# ESP32S31_RADIO register map
Vendor: Espressif; Series: ESP32-S31; File version: 3.52
Registers are 32-bit, read-write, no defined reset value unless marked. A register's access mark holds for its fields unless they carry their own. Offsets are from the block's base; [hi:lo] are bit positions; {n}, {i} and the like mark numbered series; 'fields as' and 'values as' point back to an identical list.

## IEEE802154_MAC — Dedicated ESP32-S31 IEEE 802.15.4 MAC aperture at 0x20103000. This selective foundation publishes only register geometry exercised by the pinned public common/chip LL accessors. The public struct and register headers still carry TODO ZB-93 pending an authoritative regdesc CSV, so untouched DTM, timing, debug-selector and modem-sleep words remain deliberately absent and no reset values are claimed.
Base 0x20103000
0x00 COMMAND wo — Write-only IEEE 802.15.4 MAC command opcode. The public common LL constrains commands to the listed values.
  [7:0] OPCODE
    on write: 65=TX_START; 66=RX_START; 67=CCA_TX_START; 68=ED_START; 69=STOP; 70=TEST_TX_START; 71=TEST_RX_START; 72=TEST_STOP; 76=TIMER0_START; 77=TIMER0_STOP; 78=TIMER1_START; 79=TIMER1_STOP
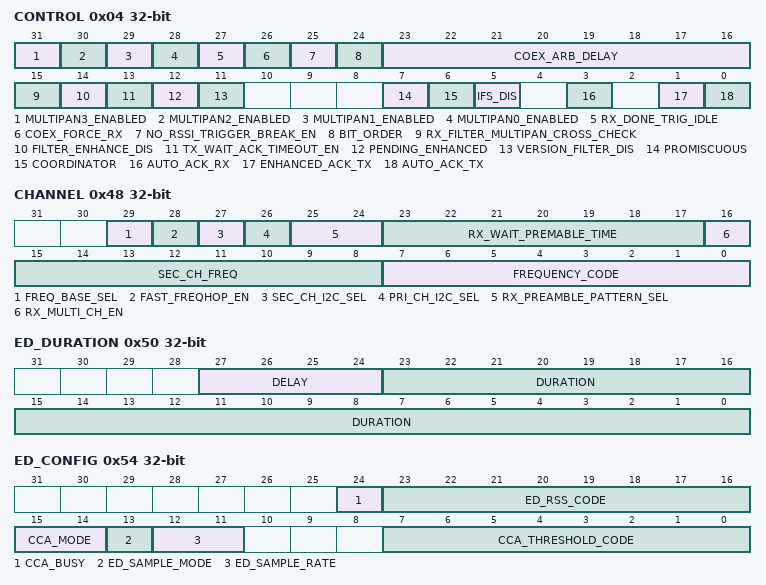
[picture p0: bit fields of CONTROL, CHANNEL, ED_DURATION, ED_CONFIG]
0x04 CONTROL — Project-assigned name. Selected MAC policy bits mutated by public common LL accessors. Unused control bits remain absent.
  [31] MULTIPAN3_ENABLED — Project-assigned name. Enable public multipan context three.
  [30] MULTIPAN2_ENABLED — Project-assigned name. Enable public multipan context two.
  [29] MULTIPAN1_ENABLED — Project-assigned name. Enable public multipan context one.
  [28] MULTIPAN0_ENABLED — Project-assigned name. Enable public multipan context zero.
  [27] RX_DONE_TRIG_IDLE — Project-assigned name. Open vendor conf.rx_done_trig_idle field. SOURCE: ESP_IDF_7B9CC1AC_S31_IEEE802154_STRUCT. No reset or additional access semantics are inferred.
  [26] COEX_FORCE_RX — Project-assigned name. Open vendor conf.coex_force_rx field. SOURCE: ESP_IDF_7B9CC1AC_S31_IEEE802154_STRUCT. No reset or additional access semantics are inferred.
  [25] NO_RSSI_TRIGGER_BREAK_EN — Project-assigned name. Open vendor conf.no_rssi_trigger_break_en field. SOURCE: ESP_IDF_7B9CC1AC_S31_IEEE802154_STRUCT. No reset or additional access semantics are inferred.
  [24] BIT_ORDER — Project-assigned name. Open vendor conf.bit_order field. SOURCE: ESP_IDF_7B9CC1AC_S31_IEEE802154_STRUCT. No reset or additional access semantics are inferred.
  [23:16] COEX_ARB_DELAY — Project-assigned name. Open vendor conf.coex_arb_delay field. SOURCE: ESP_IDF_7B9CC1AC_S31_IEEE802154_STRUCT. No reset or additional access semantics are inferred.
  [15] RX_FILTER_MULTIPAN_CROSS_CHECK — Project-assigned name. Open vendor conf.rx_filter_multipan_cross_check field. SOURCE: ESP_IDF_7B9CC1AC_S31_IEEE802154_STRUCT. No reset or additional access semantics are inferred.
  [14] FILTER_ENHANCE_DIS — Project-assigned name. Open vendor conf.filter_enhance_dis field. SOURCE: ESP_IDF_7B9CC1AC_S31_IEEE802154_STRUCT. No reset or additional access semantics are inferred.
  [13] TX_WAIT_ACK_TIMEOUT_EN — Project-assigned name. Open vendor conf.tx_wait_ack_timeout_en field. SOURCE: ESP_IDF_7B9CC1AC_S31_IEEE802154_STRUCT. No reset or additional access semantics are inferred.
  [12] PENDING_ENHANCED — Project-assigned name. Boolean pending-mode selector used by the current public LL. The wider public pending-mode enum is not encoded in this one-bit field.
  [11] VERSION_FILTER_DIS — Project-assigned name. Open vendor conf.version_filter_dis field. SOURCE: ESP_IDF_7B9CC1AC_S31_IEEE802154_STRUCT. No reset or additional access semantics are inferred.
  [7] PROMISCUOUS — Project-assigned name.
  [6] COORDINATOR — Project-assigned name.
  [5] IFS_DIS — Project-assigned name. Open vendor conf.ifs_dis field. SOURCE: ESP_IDF_7B9CC1AC_S31_IEEE802154_STRUCT. No reset or additional access semantics are inferred.
  [3] AUTO_ACK_RX — Project-assigned name.
  [1] ENHANCED_ACK_TX — Project-assigned name.
  [0] AUTO_ACK_TX — Project-assigned name.
{0x8+0x10*i} MULTIPAN{i}_SHORT_ADDRESS (i=0..3) — Project-assigned name. Sixteen-bit short address for one public multipan context.
  [15:0] ADDRESS — Project-assigned name.
{0xC+0x10*i} MULTIPAN{i}_PAN_ID (i=0..3) — Project-assigned name. Sixteen-bit PAN identifier for one public multipan context.
  [15:0] PAN_ID — Project-assigned name.
{0x10+0x10*i} MULTIPAN{i}_EXTENDED_ADDRESS_LOW (i=0..3) — Project-assigned name. Extended-address bytes zero through three packed little-endian by the public common LL.
  [31:0] ADDRESS_WORD — Project-assigned name.
{0x14+0x10*i} MULTIPAN{i}_EXTENDED_ADDRESS_HIGH (i=0..3) — Project-assigned name. Extended-address bytes four through seven packed little-endian by the public common LL.
  [31:0] ADDRESS_WORD — Project-assigned name.
0x48 CHANNEL — Selected primary frequency code. Other multi-channel and frequency-hop controls declared by the struct are not used by the public common LL and remain absent.
  [29] FREQ_BASE_SEL — Project-assigned name. Open vendor channel.freq_base_sel field. SOURCE: ESP_IDF_7B9CC1AC_S31_IEEE802154_STRUCT. No reset or additional access semantics are inferred.
  [28] FAST_FREQHOP_EN — Project-assigned name. Open vendor channel.fast_freqhop_en field. SOURCE: ESP_IDF_7B9CC1AC_S31_IEEE802154_STRUCT. No reset or additional access semantics are inferred.
  [27] SEC_CH_I2C_SEL — Project-assigned name. Open vendor channel.sec_ch_i2c_sel field. SOURCE: ESP_IDF_7B9CC1AC_S31_IEEE802154_STRUCT. No reset or additional access semantics are inferred.
  [26] PRI_CH_I2C_SEL — Project-assigned name. Open vendor channel.pri_ch_i2c_sel field. SOURCE: ESP_IDF_7B9CC1AC_S31_IEEE802154_STRUCT. No reset or additional access semantics are inferred.
  [25:24] RX_PREAMBLE_PATTERN_SEL — Project-assigned name. Open vendor channel.rx_preamble_pattern_sel field. SOURCE: ESP_IDF_7B9CC1AC_S31_IEEE802154_STRUCT. No reset or additional access semantics are inferred.
  [23:17] RX_WAIT_PREMABLE_TIME — Project-assigned name. Open vendor channel.rx_wait_premable_time field. SOURCE: ESP_IDF_7B9CC1AC_S31_IEEE802154_STRUCT. No reset or additional access semantics are inferred.
  [16] RX_MULTI_CH_EN — Project-assigned name. Open vendor channel.rx_multi_ch_en field. SOURCE: ESP_IDF_7B9CC1AC_S31_IEEE802154_STRUCT. No reset or additional access semantics are inferred.
  [15:8] SEC_CH_FREQ — Project-assigned name. Open vendor channel.sec_ch_freq field. SOURCE: ESP_IDF_7B9CC1AC_S31_IEEE802154_STRUCT. No reset or additional access semantics are inferred.
  [7:0] FREQUENCY_CODE — Project-assigned name. Eight-bit code read and written by ieee802154_ll_get_freq/set_freq; this register model does not equate it to an IEEE channel number.
0x4C TX_POWER — Eight-bit transmit-power code written through a preserving bitfield update by the public common LL.
  [7:0] POWER_CODE — Project-assigned name. Raw eight-bit hardware code; no dBm conversion is claimed at the register boundary.
0x50 ED_DURATION — Project-assigned name. Energy-detection duration field written by the public common LL. The adjacent delay field is not used there and remains absent.
  [27:24] DELAY — Project-assigned name. Open vendor ed_duration.delay field. SOURCE: ESP_IDF_7B9CC1AC_S31_IEEE802154_STRUCT. No reset or additional access semantics are inferred.
  [23:0] DURATION — Project-assigned name. Twenty-four-bit physical field. The current public setter accepts only a uint16_t and therefore exercises a strict subset of its declared range.
0x54 ED_CONFIG — Project-assigned name. Energy-detection and clear-channel-assessment configuration plus read-only result fields used by the public common LL. The pinned reg macros call bits 12:11 ED_SAMPLE_MODE and bit 13 DIS_ED_POWER_SEL, while the pinned struct/common LL operate them as ED_SAMPLE_RATE and ED_SAMPLE_MODE respectively; this model follows the operational struct/common-LL pair and leaves the naming conflict explicit.
  [24] CCA_BUSY ro
  [23:16] ED_RSS_CODE ro — Project-assigned name. Eight-bit result returned as int8_t by the public common LL.
  [15:14] CCA_MODE
    on write: 0=CARRIER; 1=ENERGY_DETECTION; 2=CARRIER_OR_ENERGY_DETECTION; 3=CARRIER_AND_ENERGY_DETECTION
  [13] ED_SAMPLE_MODE
    on write: 0=MAXIMUM; 1=AVERAGE
  [12:11] ED_SAMPLE_RATE — Project-assigned name.
    on write: 0=ONE_PER_US; 1=TWO_PER_US; 2=FOUR_PER_US; 3=EIGHT_PER_US
  [7:0] CCA_THRESHOLD_CODE — Project-assigned name. Eight-bit code written from an int8_t; signed physical units are intentionally left to the HAL.
0x5C ACK_TIMEOUT — Sixteen-bit acknowledgment timeout read and written by the public common LL. Units are not assigned by this register model.
  [15:0] TIMEOUT — Project-assigned name.
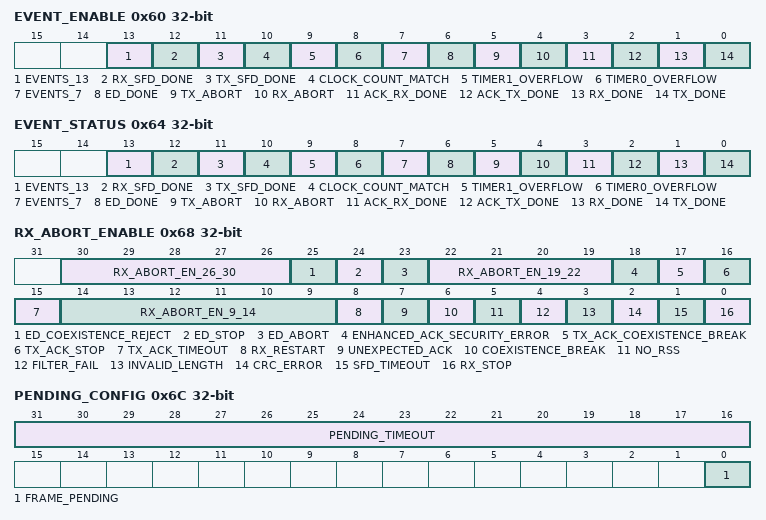
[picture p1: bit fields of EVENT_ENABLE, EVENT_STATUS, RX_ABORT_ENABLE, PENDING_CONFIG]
0x60 EVENT_ENABLE — Project-assigned name. Individual event enables mutated by the public common LL. All fourteen lanes belong to the open vendor events field; individual unnamed events remain descriptive partitions.
  [13] EVENTS_13 — Project-assigned name. Partition of the open vendor events field, bits 13:13; no individual event/reason meaning is assigned. SOURCE: ESP_IDF_7B9CC1AC_S31_IEEE802154_STRUCT.
  [12] RX_SFD_DONE — Project-assigned name.
  [11] TX_SFD_DONE — Project-assigned name.
  [10] CLOCK_COUNT_MATCH — Project-assigned name.
  [9] TIMER1_OVERFLOW — Project-assigned name.
  [8] TIMER0_OVERFLOW — Project-assigned name.
  [7] EVENTS_7 — Project-assigned name. Partition of the open vendor events field, bits 7:7; no individual event/reason meaning is assigned. SOURCE: ESP_IDF_7B9CC1AC_S31_IEEE802154_STRUCT.
  [6] ED_DONE — Project-assigned name.
  [5] TX_ABORT — Project-assigned name.
  [4] RX_ABORT — Project-assigned name.
  [3] ACK_RX_DONE — Project-assigned name.
  [2] ACK_TX_DONE — Project-assigned name.
  [1] RX_DONE — Project-assigned name.
  [0] TX_DONE — Project-assigned name.
0x64 EVENT_STATUS write-1-clears — Project-assigned name. Individual event status bits read by the public LL. The target-reviewed overlay assigns the read-write W1C contract for the applicable ESP32-S31 revision; unnamed event lanes remain partitions of the open vendor events field.
  fields as EVENT_ENABLE
0x68 RX_ABORT_ENABLE — Project-assigned name. Low thirty-one receive-abort enable bits mutated by public LL accessors. Only the finite abort-reason values named by the LL are semantically classified.
  [30:26] RX_ABORT_EN_26_30 — Project-assigned name. Partition of the open vendor rx_abort_en field, bits 30:26; no individual event/reason meaning is assigned. SOURCE: ESP_IDF_7B9CC1AC_S31_IEEE802154_STRUCT.
  [25] ED_COEXISTENCE_REJECT — Project-assigned name. Enable bit of abort reason 26 (ed coexistence reject).
  [24] ED_STOP — Project-assigned name. Enable bit of abort reason 25 (ed stop).
  [23] ED_ABORT — Project-assigned name. Enable bit of abort reason 24 (ed abort).
  [22:19] RX_ABORT_EN_19_22 — Project-assigned name. Partition of the open vendor rx_abort_en field, bits 22:19; no individual event/reason meaning is assigned. SOURCE: ESP_IDF_7B9CC1AC_S31_IEEE802154_STRUCT.
  [18] ENHANCED_ACK_SECURITY_ERROR — Project-assigned name. Enable bit of abort reason 19 (enhanced ack security error).
  [17] TX_ACK_COEXISTENCE_BREAK — Project-assigned name. Enable bit of abort reason 18 (tx ack coexistence break).
  [16] TX_ACK_STOP — Project-assigned name. Enable bit of abort reason 17 (tx ack stop).
  [15] TX_ACK_TIMEOUT — Project-assigned name. Enable bit of abort reason 16 (tx ack timeout).
  [14:9] RX_ABORT_EN_9_14 — Project-assigned name. Partition of the open vendor rx_abort_en field, bits 14:9; no individual event/reason meaning is assigned. SOURCE: ESP_IDF_7B9CC1AC_S31_IEEE802154_STRUCT.
  [8] RX_RESTART — Project-assigned name. Enable bit of abort reason 9 (rx restart).
  [7] UNEXPECTED_ACK — Project-assigned name. Enable bit of abort reason 8 (unexpected ack).
  [6] COEXISTENCE_BREAK — Project-assigned name. Enable bit of abort reason 7 (coexistence break).
  [5] NO_RSS — Project-assigned name. Enable bit of abort reason 6 (no rss).
  [4] FILTER_FAIL — Project-assigned name. Enable bit of abort reason 5 (filter fail).
  [3] INVALID_LENGTH — Project-assigned name. Enable bit of abort reason 4 (invalid length).
  [2] CRC_ERROR — Project-assigned name. Enable bit of abort reason 3 (crc error).
  [1] SFD_TIMEOUT — Project-assigned name. Enable bit of abort reason 2 (sfd timeout).
  [0] RX_STOP — Project-assigned name. Enable bit of abort reason 1 (rx stop).
0x6C PENDING_CONFIG — Project-assigned name. Selected outgoing acknowledgment frame-pending bit. The untouched timeout field remains absent.
  [31:16] PENDING_TIMEOUT — Project-assigned name. Open vendor pending_cfg.pending_timeout field. SOURCE: ESP_IDF_7B9CC1AC_S31_IEEE802154_STRUCT. No reset or additional access semantics are inferred.
  [0] FRAME_PENDING — Project-assigned name.
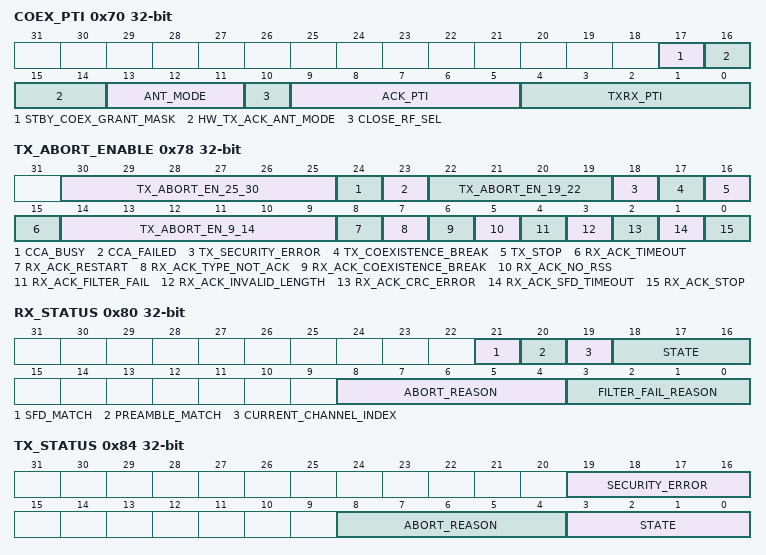
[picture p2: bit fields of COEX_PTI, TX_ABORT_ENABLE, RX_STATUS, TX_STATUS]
0x70 COEX_PTI — Selected coexistence priority fields. The public disable-coexistence helper writes value three to each through two preserving field updates. Other antenna and RF controls remain absent.
  [17] STBY_COEX_GRANT_MASK — Project-assigned name. Open vendor pti.stby_coex_grant_mask field. SOURCE: ESP_IDF_7B9CC1AC_S31_IEEE802154_STRUCT. No reset or additional access semantics are inferred.
  [16:14] HW_TX_ACK_ANT_MODE — Project-assigned name. Open vendor pti.hw_tx_ack_ant_mode field. SOURCE: ESP_IDF_7B9CC1AC_S31_IEEE802154_STRUCT. No reset or additional access semantics are inferred.
  [13:11] ANT_MODE — Project-assigned name. Open vendor pti.ant_mode field. SOURCE: ESP_IDF_7B9CC1AC_S31_IEEE802154_STRUCT. No reset or additional access semantics are inferred.
  [10] CLOSE_RF_SEL — Project-assigned name. Open vendor pti.close_rf_sel field. SOURCE: ESP_IDF_7B9CC1AC_S31_IEEE802154_STRUCT. No reset or additional access semantics are inferred.
  [9:5] ACK_PTI — Project-assigned name.
  [4:0] TXRX_PTI — Project-assigned name.
0x78 TX_ABORT_ENABLE — Project-assigned name. Low thirty-one transmit-abort enable bits mutated by public LL accessors. Only the finite abort-reason values named by the LL are semantically classified.
  [30:25] TX_ABORT_EN_25_30 — Project-assigned name. Partition of the open vendor tx_abort_en field, bits 30:25; no individual event/reason meaning is assigned. SOURCE: ESP_IDF_7B9CC1AC_S31_IEEE802154_STRUCT.
  [24] CCA_BUSY — Project-assigned name. Enable bit of abort reason 25 (cca busy).
  [23] CCA_FAILED — Project-assigned name. Enable bit of abort reason 24 (cca failed).
  [22:19] TX_ABORT_EN_19_22 — Project-assigned name. Partition of the open vendor tx_abort_en field, bits 22:19; no individual event/reason meaning is assigned. SOURCE: ESP_IDF_7B9CC1AC_S31_IEEE802154_STRUCT.
  [18] TX_SECURITY_ERROR — Project-assigned name. Enable bit of abort reason 19 (tx security error).
  [17] TX_COEXISTENCE_BREAK — Project-assigned name. Enable bit of abort reason 18 (tx coexistence break).
  [16] TX_STOP — Project-assigned name. Enable bit of abort reason 17 (tx stop).
  [15] RX_ACK_TIMEOUT — Project-assigned name. Enable bit of abort reason 16 (rx ack timeout).
  [14:9] TX_ABORT_EN_9_14 — Project-assigned name. Partition of the open vendor tx_abort_en field, bits 14:9; no individual event/reason meaning is assigned. SOURCE: ESP_IDF_7B9CC1AC_S31_IEEE802154_STRUCT.
  [8] RX_ACK_RESTART — Project-assigned name. Enable bit of abort reason 9 (rx ack restart).
  [7] RX_ACK_TYPE_NOT_ACK — Project-assigned name. Enable bit of abort reason 8 (rx ack type not ack).
  [6] RX_ACK_COEXISTENCE_BREAK — Project-assigned name. Enable bit of abort reason 7 (rx ack coexistence break).
  [5] RX_ACK_NO_RSS — Project-assigned name. Enable bit of abort reason 6 (rx ack no rss).
  [4] RX_ACK_FILTER_FAIL — Project-assigned name. Enable bit of abort reason 5 (rx ack filter fail).
  [3] RX_ACK_INVALID_LENGTH — Project-assigned name. Enable bit of abort reason 4 (rx ack invalid length).
  [2] RX_ACK_CRC_ERROR — Project-assigned name. Enable bit of abort reason 3 (rx ack crc error).
  [1] RX_ACK_SFD_TIMEOUT — Project-assigned name. Enable bit of abort reason 2 (rx ack sfd timeout).
  [0] RX_ACK_STOP — Project-assigned name. Enable bit of abort reason 1 (rx ack stop).
0x7C ENHANCED_ACK_NOTIFY wo — Project-assigned name. Write-only enhanced-ack generation-done notification word. The public common LL writes the complete value one; trigger/clear behavior is not inferred.
  [31:0] NOTIFY_IMAGE — Project-assigned name.
0x80 RX_STATUS ro — Receive status snapshot returned whole by the public common LL; selected subfields are independently named by the struct and accessor set.
  [21] SFD_MATCH
  [20] PREAMBLE_MATCH
  [19] CURRENT_CHANNEL_INDEX — Project-assigned name.
  [18:16] STATE — Project-assigned name. Three-bit receive state. The public LL only establishes that value one is RECEIVE_SFD and tests for later states with a greater-than comparison.
  [8:4] ABORT_REASON — Project-assigned name.
    on read: 1=RX_STOP; 2=SFD_TIMEOUT; 3=CRC_ERROR; 4=INVALID_LENGTH; 5=FILTER_FAIL; 6=NO_RSS; 7=COEX_BREAK; 8=UNEXPECTED_ACK; 9=RX_RESTART; 16=TX_ACK_TIMEOUT; 17=TX_ACK_STOP; 18=TX_ACK_COEX_BREAK; 19=ENHANCED_ACK_SECURITY_ERROR; 24=ED_ABORT; 25=ED_STOP; 26=ED_COEX_REJECT
  [3:0] FILTER_FAIL_REASON — Project-assigned name.
0x84 TX_STATUS ro — Transmit status snapshot returned whole by the public common LL; abort and security-error subfields have public finite reason enums.
  [19:16] SECURITY_ERROR — Project-assigned name.
    on read: 1=FRAME_CONTROL_NOT_SET; 2=RESERVED_SECURITY_LEVEL; 3=HEADER_PARSE; 4=PAYLOAD_ERROR; 5=FRAME_COUNTER_SUPPRESSION
  [8:4] ABORT_REASON — Project-assigned name.
    on read: 1=RX_ACK_STOP; 2=RX_ACK_SFD_TIMEOUT; 3=RX_ACK_CRC_ERROR; 4=RX_ACK_INVALID_LENGTH; 5=RX_ACK_FILTER_FAIL; 6=RX_ACK_NO_RSS; 7=RX_ACK_COEX_BREAK; 8=RX_ACK_TYPE_NOT_ACK; 9=RX_ACK_RESTART; 16=RX_ACK_TIMEOUT; 17=TX_STOP; 18=TX_COEX_BREAK; 19=TX_SECURITY_ERROR; 24=CCA_FAILED; 25=CCA_BUSY
  [3:0] STATE — Project-assigned name.
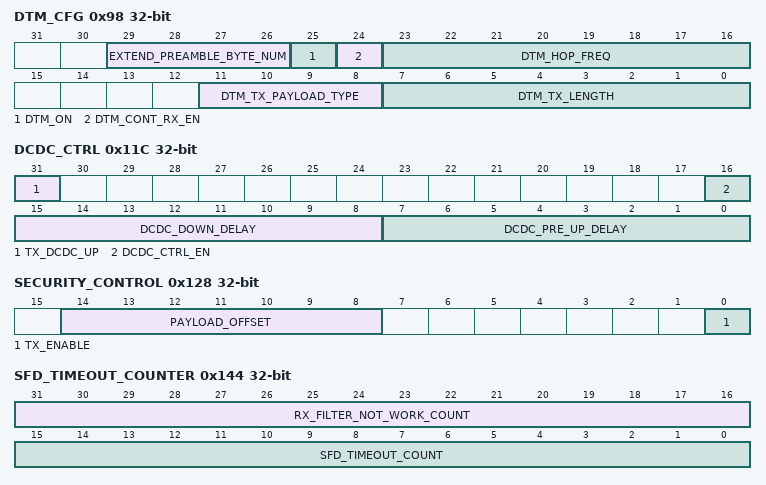
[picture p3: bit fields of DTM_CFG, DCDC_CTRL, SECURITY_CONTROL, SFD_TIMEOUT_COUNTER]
0x98 DTM_CFG access not given — Project-assigned name. Open vendor dtm_cfg word. SOURCE: ESP_IDF_7B9CC1AC_S31_IEEE802154_STRUCT. No reset value is claimed.
  [29:26] EXTEND_PREAMBLE_BYTE_NUM — Project-assigned name.
  [25] DTM_ON — Project-assigned name.
  [24] DTM_CONT_RX_EN — Project-assigned name.
  [23:16] DTM_HOP_FREQ — Project-assigned name.
  [11:8] DTM_TX_PAYLOAD_TYPE — Project-assigned name.
  [7:0] DTM_TX_LENGTH — Project-assigned name.
0xA8 TIMER0_THRESHOLD wo — Project-assigned name. Complete timer-zero threshold word written by the public common LL.
  [31:0] THRESHOLD — Project-assigned name.
0xAC TIMER0_VALUE ro — Project-assigned name. Complete timer-zero value word read by the public common LL.
  [31:0] VALUE — Project-assigned name.
0xB0 TIMER1_THRESHOLD wo — Project-assigned name. Complete timer-one threshold word written by the public common LL.
  [31:0] THRESHOLD — Project-assigned name.
0xB4 TIMER1_VALUE ro — Project-assigned name. Complete timer-one value word read by the public common LL.
  [31:0] VALUE — Project-assigned name.
0xC4 SFD_WAIT access not given — Project-assigned name. Open vendor sfd_wait word. SOURCE: ESP_IDF_7B9CC1AC_S31_IEEE802154_STRUCT. No reset value is claimed.
  [3:0] SFD_WAIT_SYMBOL_NUM — Project-assigned name.
0xD0 TX_DMA_ADDRESS wo — Project-assigned name. Complete transmit frame-buffer address written by the public common LL. Address validity and buffer lifetime remain HAL responsibilities.
  [31:0] ADDRESS — Project-assigned name.
0xD8 TXDMA_ERR ro — Transmit DMA error code, named by the public register header; no public LL accessor reads it.
  [3:0] TXDMA_ERR — Transmit DMA error code; no value is assigned a meaning.
0xE0 RX_DMA_ADDRESS wo — Project-assigned name. Complete receive frame-buffer address written by the public common LL. Address validity and buffer lifetime remain HAL responsibilities.
  [31:0] ADDRESS — Project-assigned name.
0xE8 RXDMA_ERR ro — Receive DMA error code, named by the public register header; no public LL accessor reads it.
  [3:0] RXDMA_ERR — Receive DMA error code; no value is assigned a meaning.
0x100 PAON_DELAY — Power-amplifier-on delay. The pinned public driver and LL never write it; the reset value applies unless another owner does. Physical units remain outside the PAC.
  [9:0] PAON_DELAY — Ten-bit power-amplifier-on delay.
0x104 TXON_DELAY — Transmit-on delay written by the pinned ESP32-S31 IEEE 802.15.4 MAC initializer. The literal value 45 is reviewed; Physical units remain outside the PAC.
  [9:0] TXON_DELAY — Ten-bit preserving field written with literal 45 by ieee802154_txon_delay_set.
0x108 TXEN_STOP_DELAY — Transmit-enable stop delay. The pinned public driver and LL never write it; physical units remain outside the PAC.
  [5:0] TXEN_STOP_DLY — Six-bit transmit-enable stop delay.
0x10C TXOFF_DELAY — Transmit-off delay written by the pinned ESP32-S31 IEEE 802.15.4 MAC initializer. The literal value 5 is reviewed; Physical units remain outside the PAC.
  [5:0] TXOFF_DELAY — Six-bit preserving field written with literal 5 by ieee802154_txon_delay_set.
0x110 RXON_DELAY — Receive-on delay written by the pinned ESP32-S31 IEEE 802.15.4 MAC initializer. The literal value 50 is reviewed; Physical units remain outside the PAC.
  [10:0] RXON_DELAY — Eleven-bit preserving field written with literal 50 by ieee802154_txon_delay_set.
0x114 TXRX_SWITCH_DELAY — Transmit/receive turnaround delay written by the pinned ESP32-S31 IEEE 802.15.4 MAC initializer. The literal value 117 is reviewed; Physical units remain outside the PAC.
  [9:0] TXRX_SWITCH_DELAY — Ten-bit preserving field written with literal 117 by ieee802154_txon_delay_set.
0x118 CONT_RX_DELAY — Continuous-receive delay. The pinned public driver and LL never write it; physical units remain outside the PAC.
  [5:0] CONT_RX_DELAY — Six-bit continuous-receive delay.
0x11C DCDC_CTRL — MAC control of the DC-DC converter around transmission. The pinned public driver and LL never write it; physical units of the delays remain outside the PAC.
  [31] TX_DCDC_UP — Raise the DC-DC converter for transmission.
  [16] DCDC_CTRL_EN — The MAC controls the DC-DC converter.
  [15:8] DCDC_DOWN_DELAY — Delay before the DC-DC drop.
  [7:0] DCDC_PRE_UP_DELAY — Delay before the DC-DC raise.
0x128 SECURITY_CONTROL — Project-assigned name. Transmit-security enable and payload-offset fields used by the public common LL.
  [14:8] PAYLOAD_OFFSET — Project-assigned name.
  [0] TX_ENABLE — Project-assigned name.
0x12C SECURITY_ADDRESS_LOW wo — Project-assigned name. Security extended-address bytes zero through three packed little-endian by the public common LL.
  [31:0] ADDRESS_WORD — Project-assigned name.
0x130 SECURITY_ADDRESS_HIGH wo — Project-assigned name. Security extended-address bytes four through seven packed little-endian by the public common LL.
  [31:0] ADDRESS_WORD — Project-assigned name.
{0x134+4i} SECURITY_KEY{i} (i=0..3) wo — Project-assigned name. One little-endian four-byte word of the sixteen-byte transmit-security key written by the public common LL. Key lifecycle and zeroization remain HAL obligations.
  [31:0] KEY_WORD — Project-assigned name.
0x144 SFD_TIMEOUT_COUNTER ro — Project-assigned name. Two read-only diagnostic counters independently read by the common and ESP32-S31 LL headers.
  [31:16] RX_FILTER_NOT_WORK_COUNT — Project-assigned name.
  [15:0] SFD_TIMEOUT_COUNT — Project-assigned name.
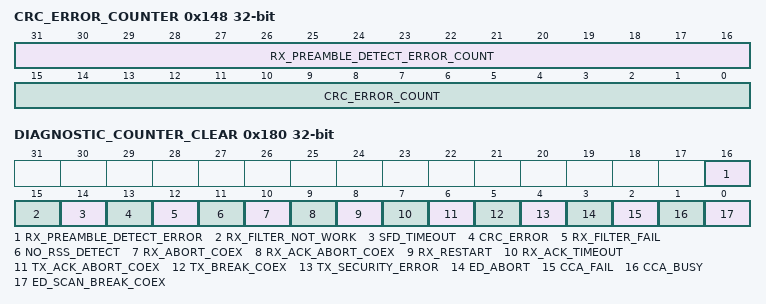
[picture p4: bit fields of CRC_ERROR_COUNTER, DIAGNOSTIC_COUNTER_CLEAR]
0x148 CRC_ERROR_COUNTER ro — Project-assigned name. Two read-only diagnostic counters independently read by the common and ESP32-S31 LL headers.
  [31:16] RX_PREAMBLE_DETECT_ERROR_COUNT — Project-assigned name.
  [15:0] CRC_ERROR_COUNT — Project-assigned name.
0x14C ED_ABORT_COUNTER ro — Project-assigned name.
  [15:0] COUNT
0x150 CCA_FAIL_COUNTER ro — Project-assigned name.
  [15:0] COUNT
0x154 RX_FILTER_FAIL_COUNTER ro — Project-assigned name.
  [15:0] COUNT
0x158 NO_RSS_DETECT_COUNTER ro — Project-assigned name.
  [15:0] COUNT
0x15C RX_ABORT_COEX_COUNTER ro — Project-assigned name.
  [15:0] COUNT
0x160 RX_RESTART_COUNTER ro — Project-assigned name.
  [15:0] COUNT
0x164 TX_ACK_ABORT_COEX_COUNTER ro — Project-assigned name.
  [15:0] COUNT
0x168 ED_SCAN_BREAK_COEX_COUNTER ro — Project-assigned name.
  [15:0] COUNT
0x16C RX_ACK_ABORT_COEX_COUNTER ro — Project-assigned name.
  [15:0] COUNT
0x170 RX_ACK_TIMEOUT_COUNTER ro — Project-assigned name.
  [15:0] COUNT
0x174 TX_BREAK_COEX_COUNTER ro — Project-assigned name.
  [15:0] COUNT
0x178 TX_SECURITY_ERROR_COUNTER ro — Project-assigned name.
  [15:0] COUNT
0x17C CCA_BUSY_COUNTER ro — Project-assigned name.
  [15:0] COUNT
0x180 DIAGNOSTIC_COUNTER_CLEAR wo — Project-assigned name. Write-only clear bitmap for the seventeen named diagnostic counters. The public common LL writes a complete caller-supplied image; no self-clearing timing is inferred.
  [16] RX_PREAMBLE_DETECT_ERROR — Project-assigned name.
  [15] RX_FILTER_NOT_WORK — Project-assigned name.
  [14] SFD_TIMEOUT — Project-assigned name.
  [13] CRC_ERROR — Project-assigned name.
  [12] RX_FILTER_FAIL — Project-assigned name.
  [11] NO_RSS_DETECT — Project-assigned name.
  [10] RX_ABORT_COEX — Project-assigned name.
  [9] RX_ACK_ABORT_COEX — Project-assigned name.
  [8] RX_RESTART — Project-assigned name.
  [7] RX_ACK_TIMEOUT — Project-assigned name.
  [6] TX_ACK_ABORT_COEX — Project-assigned name.
  [5] TX_BREAK_COEX — Project-assigned name.
  [4] TX_SECURITY_ERROR — Project-assigned name.
  [3] ED_ABORT — Project-assigned name.
  [2] CCA_FAIL — Project-assigned name.
  [1] CCA_BUSY — Project-assigned name.
  [0] ED_SCAN_BREAK_COEX — Project-assigned name.
